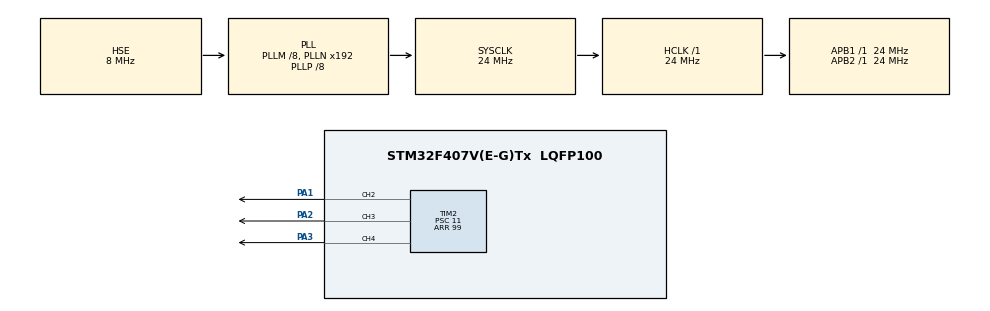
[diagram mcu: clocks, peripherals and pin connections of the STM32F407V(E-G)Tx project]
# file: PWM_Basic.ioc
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Mcu.Family=STM32F4
Mcu.Name=STM32F407V(E-G)Tx
Mcu.Package=LQFP100
NVIC.PriorityGroup=NVIC_PRIORITYGROUP_4
PA1.GPIO_Speed=GPIO_SPEED_FREQ_MEDIUM
PA1.Signal=S_TIM2_CH2
PA13.Mode=Serial_Wire
PA13.Signal=SYS_JTMS-SWDIO
PA14.Mode=Serial_Wire
PA14.Signal=SYS_JTCK-SWCLK
PA2.GPIO_Speed=GPIO_SPEED_FREQ_MEDIUM
PA2.Signal=S_TIM2_CH3
PA3.GPIO_Speed=GPIO_SPEED_FREQ_MEDIUM
PA3.Signal=S_TIM2_CH4
PH0-OSC_IN.Mode=HSE-External-Oscillator
PH0-OSC_IN.Signal=RCC_OSC_IN
PH1-OSC_OUT.Mode=HSE-External-Oscillator
PH1-OSC_OUT.Signal=RCC_OSC_OUT
ProjectManager.HeapSize=0x200
ProjectManager.StackSize=0x400
ProjectManager.TargetToolchain=STM32CubeIDE
RCC.48MHZClocksFreq_Value=48000000
RCC.AHBFreq_Value=24000000
RCC.APB1Freq_Value=24000000
RCC.APB1TimFreq_Value=24000000
RCC.APB2Freq_Value=24000000
RCC.APB2TimFreq_Value=24000000
RCC.CortexFreq_Value=24000000
RCC.EnbaleCSS=true
RCC.HCLKFreq_Value=24000000
RCC.HSE_VALUE=8000000
RCC.HSI_VALUE=16000000
RCC.LSE_VALUE=32768
RCC.PLLM=8
RCC.PLLP=RCC_PLLP_DIV8
RCC.PLLSourceVirtual=RCC_PLLSOURCE_HSE
RCC.SYSCLKFreq_VALUE=24000000
RCC.SYSCLKSource=RCC_SYSCLKSOURCE_PLLCLK
RCC.VCOOutputFreq_Value=192000000
SH.S_TIM2_CH2.0=TIM2_CH2,PWM Generation2 CH2
SH.S_TIM2_CH3.0=TIM2_CH3,PWM Generation3 CH3
SH.S_TIM2_CH4.0=TIM2_CH4,PWM Generation4 CH4
TIM2.AutoReloadPreload=TIM_AUTORELOAD_PRELOAD_ENABLE
TIM2.Channel-PWM\ Generation2\ CH2=TIM_CHANNEL_2
TIM2.Channel-PWM\ Generation3\ CH3=TIM_CHANNEL_3
TIM2.Channel-PWM\ Generation4\ CH4=TIM_CHANNEL_4
TIM2.OCPolarity_2=TIM_OCPOLARITY_LOW
TIM2.OCPolarity_3=TIM_OCPOLARITY_LOW
TIM2.OCPolarity_4=TIM_OCPOLARITY_LOW
TIM2.Period=99
TIM2.Prescaler=11
TIM2.Pulse-PWM\ Generation2\ CH2=25
TIM2.Pulse-PWM\ Generation3\ CH3=60
TIM2.Pulse-PWM\ Generation4\ CH4=90
VP_TIM2_VS_ClockSourceINT.Mode=Internal
board=custom

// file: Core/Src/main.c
/* USER CODE BEGIN Header */
/**
  ******************************************************************************
  * @file           : main.c
  * @brief          : Main program body
  ******************************************************************************
  * @attention
  *
  * Copyright (c) 2024 STMicroelectronics.
  * All rights reserved.
  *
  * This software is licensed under terms that can be found in the LICENSE file
  * in the root directory of this software component.
  * If no LICENSE file comes with this software, it is provided AS-IS.
  *
  ******************************************************************************
  */
/* USER CODE END Header */
#include "main.h"

TIM_HandleTypeDef htim2;

void SystemClock_Config(void);
static void MX_GPIO_Init(void);
static void MX_TIM2_Init(void);

int main(void)
{

  /* MCU Configuration--------------------------------------------------------*/

  /* Reset of all peripherals, Initializes the Flash interface and the Systick. */
  HAL_Init();

  /* Configure the system clock */
  SystemClock_Config();

  /* Initialize all configured peripherals */
  MX_GPIO_Init();
  MX_TIM2_Init();
  /* USER CODE BEGIN 2 */

  //Begins PWM which uses Timer 2 as base time
  HAL_TIM_PWM_Start(&htim2, TIM_CHANNEL_2); //CH2 PA1
  HAL_TIM_PWM_Start(&htim2, TIM_CHANNEL_3); //CH3 PA2
  HAL_TIM_PWM_Start(&htim2, TIM_CHANNEL_4); //CH3 PA3

  /* USER CODE END 2 */

  /* Infinite loop */
  while (1)
  {

  }
}

void SystemClock_Config(void)
{
  RCC_OscInitTypeDef RCC_OscInitStruct = {0};
  RCC_ClkInitTypeDef RCC_ClkInitStruct = {0};

  /** Configure the main internal regulator output voltage
  */
  __HAL_RCC_PWR_CLK_ENABLE();
  __HAL_PWR_VOLTAGESCALING_CONFIG(PWR_REGULATOR_VOLTAGE_SCALE1);

  /** Initializes the RCC Oscillators according to the specified parameters
  * in the RCC_OscInitTypeDef structure.
  */
  RCC_OscInitStruct.OscillatorType = RCC_OSCILLATORTYPE_HSE;
  RCC_OscInitStruct.HSEState = RCC_HSE_ON;
  RCC_OscInitStruct.PLL.PLLState = RCC_PLL_ON;
  RCC_OscInitStruct.PLL.PLLSource = RCC_PLLSOURCE_HSE;
  RCC_OscInitStruct.PLL.PLLM = 8;
  RCC_OscInitStruct.PLL.PLLN = 192;
  RCC_OscInitStruct.PLL.PLLP = RCC_PLLP_DIV8;
  RCC_OscInitStruct.PLL.PLLQ = 4;
  if (HAL_RCC_OscConfig(&RCC_OscInitStruct) != HAL_OK)
  {
    Error_Handler();
  }

  /** Initializes the CPU, AHB and APB buses clocks
  */
  RCC_ClkInitStruct.ClockType = RCC_CLOCKTYPE_HCLK|RCC_CLOCKTYPE_SYSCLK
                              |RCC_CLOCKTYPE_PCLK1|RCC_CLOCKTYPE_PCLK2;
  RCC_ClkInitStruct.SYSCLKSource = RCC_SYSCLKSOURCE_PLLCLK;
  RCC_ClkInitStruct.AHBCLKDivider = RCC_SYSCLK_DIV1;
  RCC_ClkInitStruct.APB1CLKDivider = RCC_HCLK_DIV1;
  RCC_ClkInitStruct.APB2CLKDivider = RCC_HCLK_DIV1;

  if (HAL_RCC_ClockConfig(&RCC_ClkInitStruct, FLASH_LATENCY_0) != HAL_OK)
  {
    Error_Handler();
  }

  /** Enables the Clock Security System
  */
  HAL_RCC_EnableCSS();
}

static void MX_TIM2_Init(void)
{

  TIM_ClockConfigTypeDef sClockSourceConfig = {0};
  TIM_MasterConfigTypeDef sMasterConfig = {0};
  TIM_OC_InitTypeDef sConfigOC = {0};

  htim2.Instance = TIM2;
  htim2.Init.Prescaler = 11;
  htim2.Init.CounterMode = TIM_COUNTERMODE_UP;
  htim2.Init.Period = 99;
  htim2.Init.ClockDivision = TIM_CLOCKDIVISION_DIV1;
  htim2.Init.AutoReloadPreload = TIM_AUTORELOAD_PRELOAD_ENABLE;
  if (HAL_TIM_Base_Init(&htim2) != HAL_OK)
  {
    Error_Handler();
  }
  sClockSourceConfig.ClockSource = TIM_CLOCKSOURCE_INTERNAL;
  if (HAL_TIM_ConfigClockSource(&htim2, &sClockSourceConfig) != HAL_OK)
  {
    Error_Handler();
  }
  if (HAL_TIM_PWM_Init(&htim2) != HAL_OK)
  {
    Error_Handler();
  }
  sMasterConfig.MasterOutputTrigger = TIM_TRGO_RESET;
  sMasterConfig.MasterSlaveMode = TIM_MASTERSLAVEMODE_DISABLE;
  if (HAL_TIMEx_MasterConfigSynchronization(&htim2, &sMasterConfig) != HAL_OK)
  {
    Error_Handler();
  }
  sConfigOC.OCMode = TIM_OCMODE_PWM1;
  sConfigOC.Pulse = 25;
  sConfigOC.OCPolarity = TIM_OCPOLARITY_LOW;
  sConfigOC.OCFastMode = TIM_OCFAST_DISABLE;
  if (HAL_TIM_PWM_ConfigChannel(&htim2, &sConfigOC, TIM_CHANNEL_2) != HAL_OK)
  {
    Error_Handler();
  }
  sConfigOC.Pulse = 60;
  if (HAL_TIM_PWM_ConfigChannel(&htim2, &sConfigOC, TIM_CHANNEL_3) != HAL_OK)
  {
    Error_Handler();
  }
  sConfigOC.Pulse = 90;
  if (HAL_TIM_PWM_ConfigChannel(&htim2, &sConfigOC, TIM_CHANNEL_4) != HAL_OK)
  {
    Error_Handler();
  }
  HAL_TIM_MspPostInit(&htim2);

}

static void MX_GPIO_Init(void)
{
  GPIO_InitTypeDef GPIO_InitStruct = {0};

  /* GPIO Ports Clock Enable */
  __HAL_RCC_GPIOE_CLK_ENABLE();
  __HAL_RCC_GPIOC_CLK_ENABLE();
  __HAL_RCC_GPIOH_CLK_ENABLE();
  __HAL_RCC_GPIOA_CLK_ENABLE();
  __HAL_RCC_GPIOB_CLK_ENABLE();
  __HAL_RCC_GPIOD_CLK_ENABLE();

  /*Configure GPIO pins : PE2 PE3 PE4 PE5
                           PE6 PE7 PE8 PE9
                           PE10 PE11 PE12 PE13
                           PE14 PE15 PE0 PE1 */
  GPIO_InitStruct.Pin = GPIO_PIN_2|GPIO_PIN_3|GPIO_PIN_4|GPIO_PIN_5
                          |GPIO_PIN_6|GPIO_PIN_7|GPIO_PIN_8|GPIO_PIN_9
                          |GPIO_PIN_10|GPIO_PIN_11|GPIO_PIN_12|GPIO_PIN_13
                          |GPIO_PIN_14|GPIO_PIN_15|GPIO_PIN_0|GPIO_PIN_1;
  GPIO_InitStruct.Mode = GPIO_MODE_ANALOG;
  GPIO_InitStruct.Pull = GPIO_NOPULL;
  HAL_GPIO_Init(GPIOE, &GPIO_InitStruct);

  /*Configure GPIO pins : PC13 PC14 PC15 PC0
                           PC1 PC2 PC3 PC4
                           PC5 PC6 PC7 PC8
                           PC9 PC10 PC11 PC12 */
  GPIO_InitStruct.Pin = GPIO_PIN_13|GPIO_PIN_14|GPIO_PIN_15|GPIO_PIN_0
                          |GPIO_PIN_1|GPIO_PIN_2|GPIO_PIN_3|GPIO_PIN_4
                          |GPIO_PIN_5|GPIO_PIN_6|GPIO_PIN_7|GPIO_PIN_8
                          |GPIO_PIN_9|GPIO_PIN_10|GPIO_PIN_11|GPIO_PIN_12;
  GPIO_InitStruct.Mode = GPIO_MODE_ANALOG;
  GPIO_InitStruct.Pull = GPIO_NOPULL;
  HAL_GPIO_Init(GPIOC, &GPIO_InitStruct);

  /*Configure GPIO pins : PA0 PA4 PA5 PA6
                           PA7 PA8 PA9 PA10
                           PA11 PA12 PA15 */
  GPIO_InitStruct.Pin = GPIO_PIN_0|GPIO_PIN_4|GPIO_PIN_5|GPIO_PIN_6
                          |GPIO_PIN_7|GPIO_PIN_8|GPIO_PIN_9|GPIO_PIN_10
                          |GPIO_PIN_11|GPIO_PIN_12|GPIO_PIN_15;
  GPIO_InitStruct.Mode = GPIO_MODE_ANALOG;
  GPIO_InitStruct.Pull = GPIO_NOPULL;
  HAL_GPIO_Init(GPIOA, &GPIO_InitStruct);

  /*Configure GPIO pins : PB0 PB1 PB2 PB10
                           PB11 PB12 PB13 PB14
                           PB15 PB3 PB4 PB5
                           PB6 PB7 PB8 PB9 */
  GPIO_InitStruct.Pin = GPIO_PIN_0|GPIO_PIN_1|GPIO_PIN_2|GPIO_PIN_10
                          |GPIO_PIN_11|GPIO_PIN_12|GPIO_PIN_13|GPIO_PIN_14
                          |GPIO_PIN_15|GPIO_PIN_3|GPIO_PIN_4|GPIO_PIN_5
                          |GPIO_PIN_6|GPIO_PIN_7|GPIO_PIN_8|GPIO_PIN_9;
  GPIO_InitStruct.Mode = GPIO_MODE_ANALOG;
  GPIO_InitStruct.Pull = GPIO_NOPULL;
  HAL_GPIO_Init(GPIOB, &GPIO_InitStruct);

  /*Configure GPIO pins : PD8 PD9 PD10 PD11
                           PD12 PD13 PD14 PD15
                           PD0 PD1 PD2 PD3
                           PD4 PD5 PD6 PD7 */
  GPIO_InitStruct.Pin = GPIO_PIN_8|GPIO_PIN_9|GPIO_PIN_10|GPIO_PIN_11
                          |GPIO_PIN_12|GPIO_PIN_13|GPIO_PIN_14|GPIO_PIN_15
                          |GPIO_PIN_0|GPIO_PIN_1|GPIO_PIN_2|GPIO_PIN_3
                          |GPIO_PIN_4|GPIO_PIN_5|GPIO_PIN_6|GPIO_PIN_7;
  GPIO_InitStruct.Mode = GPIO_MODE_ANALOG;
  GPIO_InitStruct.Pull = GPIO_NOPULL;
  HAL_GPIO_Init(GPIOD, &GPIO_InitStruct);

}

void Error_Handler(void)
{
  __disable_irq();
  while (1)
  {
  }
}
